# R9A09G057H register map
Vendor: Renesas Electronics; File version: 1.0
Registers are 32-bit, read-write, no defined reset value unless marked. A register's access mark holds for its fields unless they carry their own. Offsets are from the block's base; [hi:lo] are bit positions; lines under a group give offsets from that group; {n}, {i} and the like mark numbered series.

## R_GPIO — IO define file for gpio.
Base 0x10410020
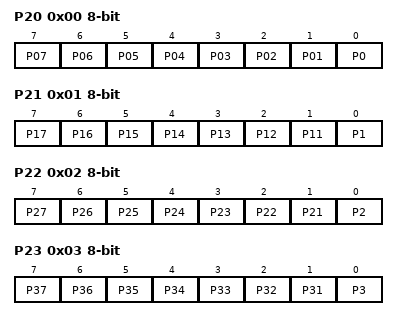
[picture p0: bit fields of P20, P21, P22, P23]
0x00 P20 8-bit
  [n] P{n:02} (n=1..7), [0] P0
0x01 P21 8-bit
  [n-10] P{n} (n=11..17), [0] P1
0x02 P22 8-bit
  [n-20] P{n} (n=21..27), [0] P2
0x03 P23 8-bit
  [n-30] P{n} (n=31..37), [0] P3
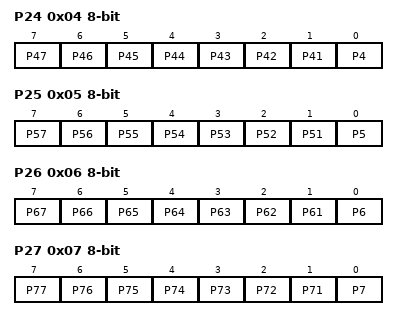
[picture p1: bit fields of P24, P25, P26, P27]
0x04 P24 8-bit
  [n-40] P{n} (n=41..47), [0] P4
0x05 P25 8-bit
  [n-50] P{n} (n=51..57), [0] P5
0x06 P26 8-bit
  [n-60] P{n} (n=61..67), [0] P6
0x07 P27 8-bit
  [n-70] P{n} (n=71..77), [0] P7
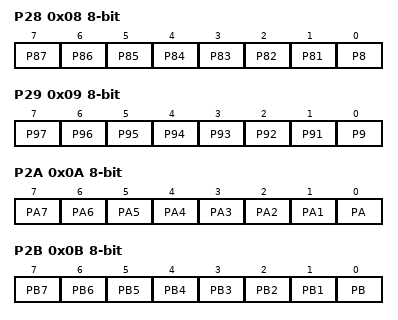
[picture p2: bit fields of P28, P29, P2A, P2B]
0x08 P28 8-bit
  [n-80] P{n} (n=81..87), [0] P8
0x09 P29 8-bit
  [n-90] P{n} (n=91..97), [0] P9
0x0A P2A 8-bit
  [n] PA{n} (n=1..7), [0] PA
0x0B P2B 8-bit
  [n] PB{n} (n=1..7), [0] PB
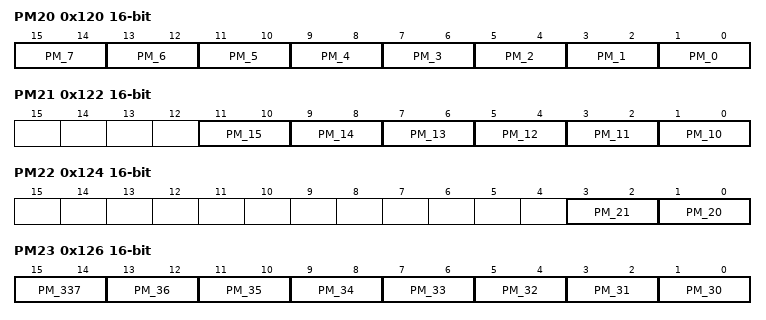
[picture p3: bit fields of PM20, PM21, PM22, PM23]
0x120 PM20 16-bit
  [2n+1:2n] PM_{n} (n=0..7)
0x122 PM21 16-bit
  [2n-19:2n-20] PM_{n} (n=10..15)
0x124 PM22 16-bit
  [3:2] PM_21, [1:0] PM_20
0x126 PM23 16-bit
  [15:14] PM_337, [2n-59:2n-60] PM_{n} (n=30..36)
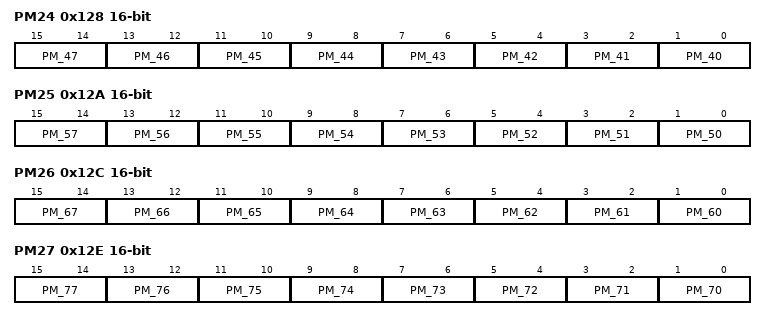
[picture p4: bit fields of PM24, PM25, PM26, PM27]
0x128 PM24 16-bit
  [2n-79:2n-80] PM_{n} (n=40..47)
0x12A PM25 16-bit
  [2n-99:2n-100] PM_{n} (n=50..57)
0x12C PM26 16-bit
  [2n-119:2n-120] PM_{n} (n=60..67)
0x12E PM27 16-bit
  [2n-139:2n-140] PM_{n} (n=70..77)
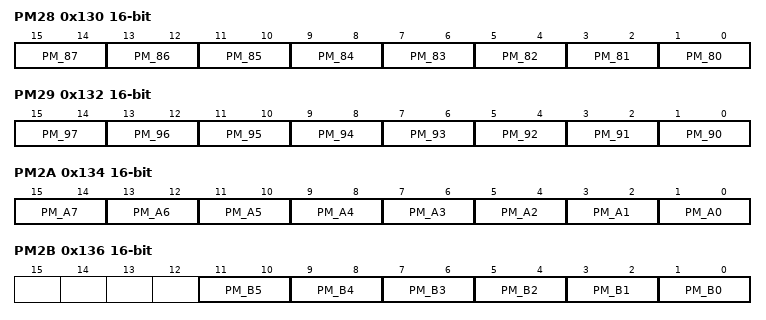
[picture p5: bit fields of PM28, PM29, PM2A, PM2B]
0x130 PM28 16-bit
  [2n-159:2n-160] PM_{n} (n=80..87)
0x132 PM29 16-bit
  [2n-179:2n-180] PM_{n} (n=90..97)
0x134 PM2A 16-bit
  [2n+1:2n] PM_A{n} (n=0..7)
0x136 PM2B 16-bit
  [2n+1:2n] PM_B{n} (n=0..5)
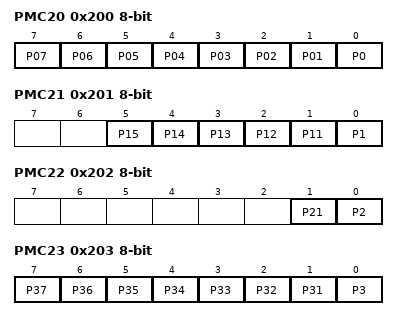
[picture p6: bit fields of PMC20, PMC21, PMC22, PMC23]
0x200 PMC20 8-bit
  [n] P{n:02} (n=1..7), [0] P0
0x201 PMC21 8-bit
  [n-10] P{n} (n=11..15), [0] P1
0x202 PMC22 8-bit
  [1] P21, [0] P2
0x203 PMC23 8-bit
  [n-30] P{n} (n=31..37), [0] P3
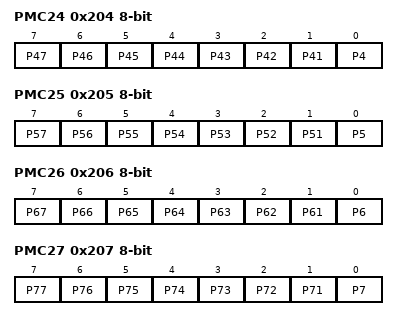
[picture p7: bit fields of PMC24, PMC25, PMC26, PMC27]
0x204 PMC24 8-bit
  [n-40] P{n} (n=41..47), [0] P4
0x205 PMC25 8-bit
  [n-50] P{n} (n=51..57), [0] P5
0x206 PMC26 8-bit
  [n-60] P{n} (n=61..67), [0] P6
0x207 PMC27 8-bit
  [n-70] P{n} (n=71..77), [0] P7
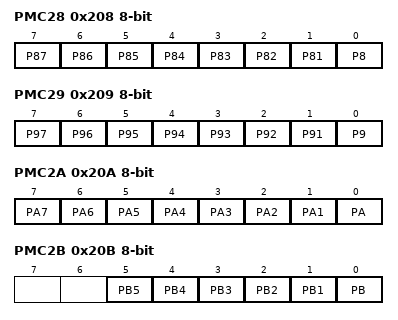
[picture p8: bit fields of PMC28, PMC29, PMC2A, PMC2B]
0x208 PMC28 8-bit
  [n-80] P{n} (n=81..87), [0] P8
0x209 PMC29 8-bit
  [n-90] P{n} (n=91..97), [0] P9
0x20A PMC2A 8-bit
  [n] PA{n} (n=1..7), [0] PA
0x20B PMC2B 8-bit
  [n] PB{n} (n=1..5), [0] PB
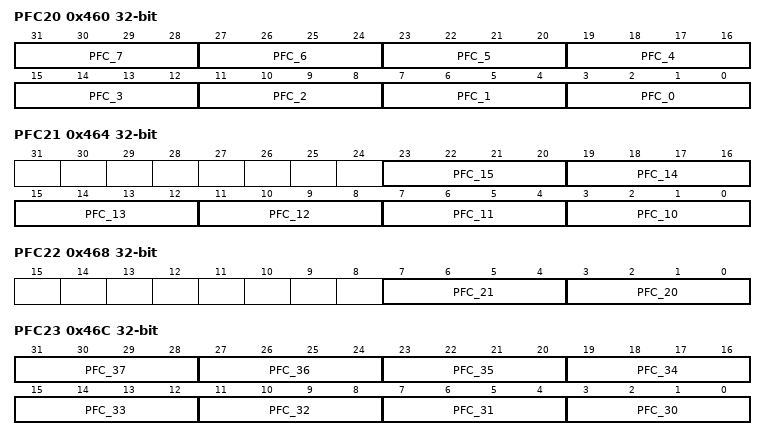
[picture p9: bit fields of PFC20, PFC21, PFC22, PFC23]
0x460 PFC20
  [4n+3:4n] PFC_{n} (n=0..7)
0x464 PFC21
  [4n-37:4n-40] PFC_{n} (n=10..15)
0x468 PFC22
  [7:4] PFC_21, [3:0] PFC_20
0x46C PFC23
  [4n-117:4n-120] PFC_{n} (n=30..37)
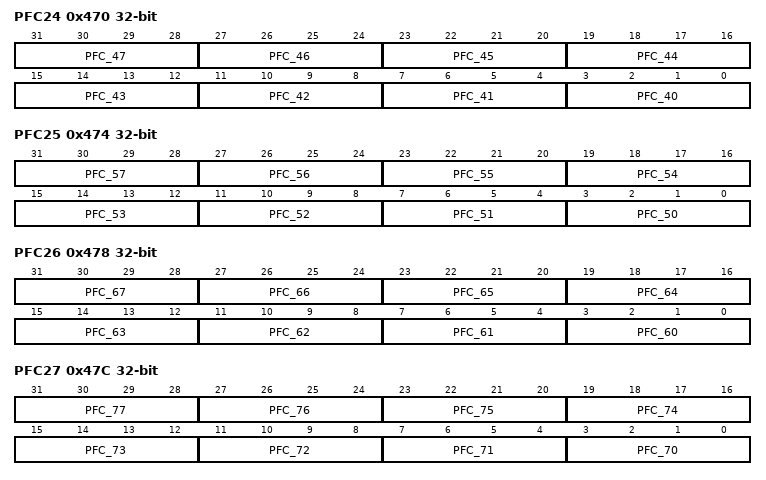
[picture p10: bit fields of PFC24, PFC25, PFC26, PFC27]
0x470 PFC24
  [4n-157:4n-160] PFC_{n} (n=40..47)
0x474 PFC25
  [4n-197:4n-200] PFC_{n} (n=50..57)
0x478 PFC26
  [4n-237:4n-240] PFC_{n} (n=60..67)
0x47C PFC27
  [4n-277:4n-280] PFC_{n} (n=70..77)
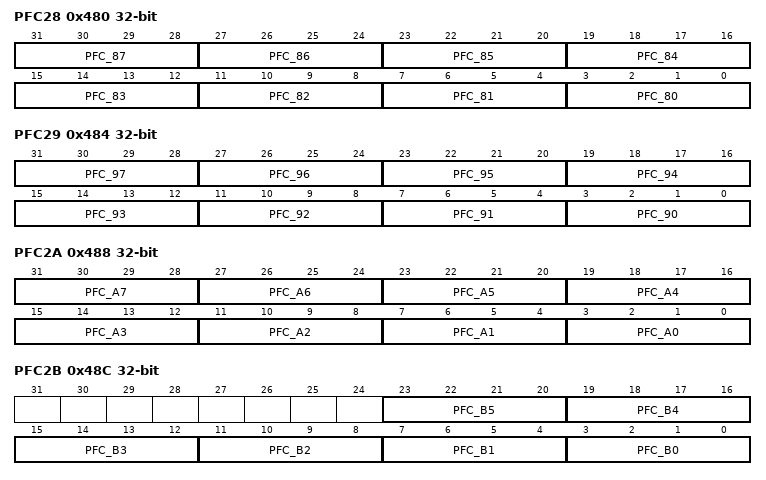
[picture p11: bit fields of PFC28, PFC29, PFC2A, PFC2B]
0x480 PFC28
  [4n-317:4n-320] PFC_{n} (n=80..87)
0x484 PFC29
  [4n-357:4n-360] PFC_{n} (n=90..97)
0x488 PFC2A
  [4n+3:4n] PFC_A{n} (n=0..7)
0x48C PFC2B
  [4n+3:4n] PFC_B{n} (n=0..5)
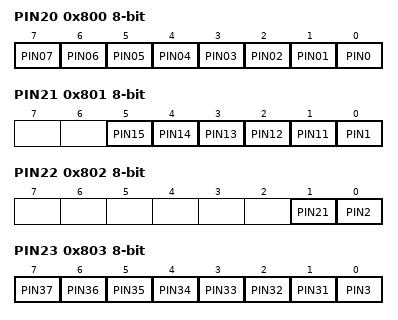
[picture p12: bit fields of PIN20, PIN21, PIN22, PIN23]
0x800 PIN20 8-bit ro
  [n] PIN{n:02} (n=1..7), [0] PIN0
0x801 PIN21 8-bit ro
  [n-10] PIN{n} (n=11..15), [0] PIN1
0x802 PIN22 8-bit ro
  [1] PIN21, [0] PIN2
0x803 PIN23 8-bit ro
  [n-30] PIN{n} (n=31..37), [0] PIN3
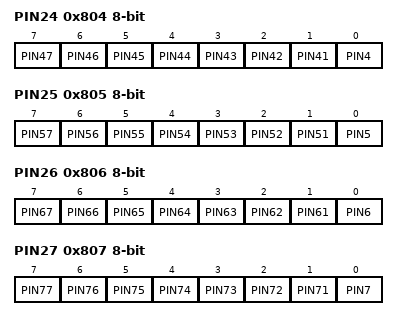
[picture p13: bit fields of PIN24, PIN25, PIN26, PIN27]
0x804 PIN24 8-bit ro
  [n-40] PIN{n} (n=41..47), [0] PIN4
0x805 PIN25 8-bit ro
  [n-50] PIN{n} (n=51..57), [0] PIN5
0x806 PIN26 8-bit ro
  [n-60] PIN{n} (n=61..67), [0] PIN6
0x807 PIN27 8-bit ro
  [n-70] PIN{n} (n=71..77), [0] PIN7
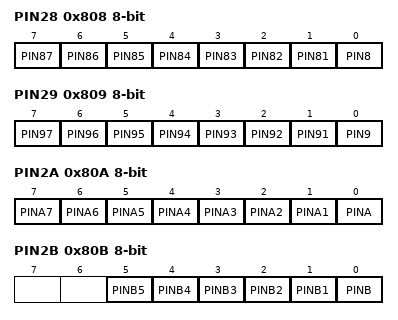
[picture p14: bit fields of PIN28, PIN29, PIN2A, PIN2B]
0x808 PIN28 8-bit ro
  [n-80] PIN{n} (n=81..87), [0] PIN8
0x809 PIN29 8-bit ro
  [n-90] PIN{n} (n=91..97), [0] PIN9
0x80A PIN2A 8-bit ro
  [n] PINA{n} (n=1..7), [0] PINA
0x80B PIN2B 8-bit ro
  [n] PINB{n} (n=1..5), [0] PINB
0xFF8 IOLH3_L
  [8n-239:8n-240] IOLH_{n} (n=30..33)
0xFFC IOLH3_H
  [8n-239:8n-240] IOLH_{n} (n=30..33)
0x1008 IOLH5_L
  [8n-399:8n-400] IOLH_{n} (n=50..53)
0x100C IOLH5_H
  [8n-399:8n-400] IOLH_{n} (n=50..53)
0x1010 IOLH6_L
  [8n-479:8n-480] IOLH_{n} (n=60..63)
0x1014 IOLH6_H
  [8n-479:8n-480] IOLH_{n} (n=60..63)
0x1018 IOLH7_L
  [8n-559:8n-560] IOLH_{n} (n=70..73)
0x101C IOLH7_H
  [8n-559:8n-560] IOLH_{n} (n=70..73)
0x1020 IOLH8_L
  [8n-639:8n-640] IOLH_{n} (n=80..83)
0x1024 IOLH8_H
  [8n-639:8n-640] IOLH_{n} (n=80..83)
0x1028 IOLH9_L
  [8n-719:8n-720] IOLH_{n} (n=90..93)
0x102C IOLH9_H
  [8n-719:8n-720] IOLH_{n} (n=90..93)
0x1030 IOLHA_L
  [8n+1:8n] IOLH_A{n} (n=0..3)
0x1034 IOLHA_H
  [8n+1:8n] IOLH_A{n} (n=0..3)
0x1038 IOLHB_L
  [8n+1:8n] IOLH_B{n} (n=0..3)
0x103C IOLHB_H
  [8n+1:8n] IOLH_B{n} (n=0..3)
0x1040 IOLHC_L
  [8n+1:8n] IOLH_C{n} (n=0..3)
0x1044 IOLHC_H
  [8n+1:8n] IOLH_C{n} (n=0..3)
0x1050 IOLHE_L
  [8n+1:8n] IOLH_E{n} (n=0..3)
0x1054 IOLHE_H
  [8n+1:8n] IOLH_E{n} (n=0..3)
0x1058 IOLHF_L
  [8n+1:8n] IOLH_F{n} (n=0..3)
0x105C IOLHF_H
  [8n+1:8n] IOLH_F{n} (n=0..3)
0x1060 IOLH10_L
  [8n-799:8n-800] IOLH_{n} (n=100..103)
0x1064 IOLH10_H
  [8n-799:8n-800] IOLH_{n} (n=100..103)
0x1068 IOLH11_L
  [8n-879:8n-880] IOLH_{n} (n=110..113)
0x106C IOLH11_H
  [8n-879:8n-880] IOLH_{n} (n=110..113)
0x1070 IOLH12_L
  [8n-959:8n-960] IOLH_{n} (n=120..123)
0x1074 IOLH12_H
  [8n-959:8n-960] IOLH_{n} (n=120..123)
0x1078 IOLH13_L
  [8n-1039:8n-1040] IOLH_{n} (n=130..133)
0x107C IOLH13_H
  [8n-1039:8n-1040] IOLH_{n} (n=130..133)
0x1080 IOLH14_L
  [8n-1119:8n-1120] IOLH_{n} (n=140..143)
0x1084 IOLH14_H
  [8n-1119:8n-1120] IOLH_{n} (n=140..143)
0x10E0 IOLH20_L
  [8n-1599:8n-1600] IOLH_{n} (n=200..203)
0x10E4 IOLH20_H
  [8n-1599:8n-1600] IOLH_{n} (n=200..203)
0x10E8 IOLH21_L
  [8n-1679:8n-1680] IOLH_{n} (n=210..213)
0x10EC IOLH21_H
  [8n-1679:8n-1680] IOLH_{n} (n=210..213)
0x10F0 IOLH22_L
  [8n-1759:8n-1760] IOLH_{n} (n=220..223)
0x10F4 IOLH22_H
  [8n-1759:8n-1760] IOLH_{n} (n=220..223)
0x10F8 IOLH23_L
  [8n-1839:8n-1840] IOLH_{n} (n=230..233)
0x10FC IOLH23_H
  [8n-1839:8n-1840] IOLH_{n} (n=230..233)
0x1100 IOLH24_L
  [8n-1919:8n-1920] IOLH_{n} (n=240..243)
0x1104 IOLH24_H
  [8n-1919:8n-1920] IOLH_{n} (n=240..243)
0x1108 IOLH25_L
  [8n-1999:8n-2000] IOLH_{n} (n=250..253)
0x110C IOLH25_H
  [8n-1999:8n-2000] IOLH_{n} (n=250..253)
0x1110 IOLH26_L
  [8n-2079:8n-2080] IOLH_{n} (n=260..263)
0x1114 IOLH26_H
  [8n-2079:8n-2080] IOLH_{n} (n=260..263)
0x1118 IOLH27_L
  [8n-2159:8n-2160] IOLH_{n} (n=270..273)
0x111C IOLH27_H
  [8n-2159:8n-2160] IOLH_{n} (n=270..273)
0x1120 IOLH28_L
  [8n-2239:8n-2240] IOLH_{n} (n=280..283)
0x1124 IOLH28_H
  [8n-2239:8n-2240] IOLH_{n} (n=280..283)
0x1128 IOLH29_L
  [8n-2319:8n-2320] IOLH_{n} (n=290..293)
0x112C IOLH29_H
  [8n-2319:8n-2320] IOLH_{n} (n=290..293)
0x1130 IOLH2A_L
  [8n+1:8n] IOLH_2A{n} (n=0..3)
0x1134 IOLH2A_H
  [8n+1:8n] IOLH_2A{n} (n=0..3)
0x1138 IOLH2B_L
  [8n+1:8n] IOLH_2B{n} (n=0..3)
0x113C IOLH2B_H
  [8n+1:8n] IOLH_2B{n} (n=0..3)
0x13F8 SR3_L
  [8n-240] SR_{n} (n=30..33)
0x13FC SR3_H
  [8n-240] SR_{n} (n=30..33)
0x1408 SR5_L
  [8n-400] SR_{n} (n=50..53)
0x140C SR5_H
  [8n-400] SR_{n} (n=50..53)
0x1410 SR6_L
  [8n-480] SR_{n} (n=60..63)
0x1414 SR6_H
  [8n-480] SR_{n} (n=60..63)
0x1418 SR7_L
  [8n-560] SR_{n} (n=70..73)
0x141C SR7_H
  [8n-560] SR_{n} (n=70..73)
0x1420 SR8_L
  [8n-640] SR_{n} (n=80..83)
0x1424 SR8_H
  [8n-640] SR_{n} (n=80..83)
0x1428 SR9_L
  [8n-720] SR_{n} (n=90..93)
0x142C SR9_H
  [8n-720] SR_{n} (n=90..93)
0x1430 SRA_L
  [8n] SR_A{n} (n=0..3)
0x1434 SRA_H
  [8n] SR_A{n} (n=0..3)
0x1438 SRB_L
  [8n] SR_B{n} (n=0..3)
0x143C SRB_H
  [8n] SR_B{n} (n=0..3)
0x1440 SRC_L
  [8n] SR_C{n} (n=0..3)
0x1444 SRC_H
  [8n] SR_C{n} (n=0..3)
0x1450 SRE_L
  [8n] SR_E{n} (n=0..3)
0x1454 SRE_H
  [8n] SR_E{n} (n=0..3)
0x1458 SRF_L
  [8n] SR_F{n} (n=0..3)
0x145C SRF_H
  [8n] SR_F{n} (n=0..3)
0x1460 SR10_L
  [8n-800] SR_{n} (n=100..103)
0x1464 SR10_H
  [8n-800] SR_{n} (n=100..103)
0x1468 SR11_L
  [8n-880] SR_{n} (n=110..113)
0x146C SR11_H
  [8n-880] SR_{n} (n=110..113)
0x1470 SR12_L
  [8n-960] SR_{n} (n=120..123)
0x1474 SR12_H
  [8n-960] SR_{n} (n=120..123)
0x1478 SR13_L
  [8n-1040] SR_{n} (n=130..133)
0x147C SR13_H
  [8n-1040] SR_{n} (n=130..133)
0x1480 SR14_L
  [8n-1120] SR_{n} (n=140..143)
0x1484 SR14_H
  [8n-1120] SR_{n} (n=140..143)
0x14E0 SR20_L
  [8n-1600] SR_{n} (n=200..203)
0x14E4 SR20_H
  [8n-1600] SR_{n} (n=200..203)
0x14E8 SR21_L
  [8n-1680] SR_{n} (n=210..213)
0x14EC SR21_H
  [8n-1680] SR_{n} (n=210..213)
0x14F8 SR23_L
  [8n-1840] SR_{n} (n=230..233)
0x14FC SR23_H
  [8n-1840] SR_{n} (n=230..233)
0x1500 SR24_L
  [8n-1920] SR_{n} (n=240..243)
0x1504 SR24_H
  [8n-1920] SR_{n} (n=240..243)
0x1508 SR25_L
  [8n-2000] SR_{n} (n=250..253)
0x150C SR25_H
  [8n-2000] SR_{n} (n=250..253)
0x1510 SR26_L
  [8n-2080] SR_{n} (n=260..263)
0x1514 SR26_H
  [8n-2080] SR_{n} (n=260..263)
0x1518 SR27_L
  [8n-2160] SR_{n} (n=270..273)
0x151C SR27_H
  [8n-2160] SR_{n} (n=270..273)
0x1520 SR28_L
  [8n-2240] SR_{n} (n=280..283)
0x1524 SR28_H
  [8n-2240] SR_{n} (n=280..283)
0x1528 SR29_L
  [8n-2320] SR_{n} (n=290..293)
0x152C SR29_H
  [8n-2320] SR_{n} (n=290..293)
0x1530 SR2A_L
  [8n] SR_2A{n} (n=0..3)
0x1534 SR2A_H
  [8n] SR_2A{n} (n=0..3)
0x1538 SR2B_L
  [8n] SR_2B{n} (n=0..3)
0x153C SR2B_H
  [8n] SR_2B{n} (n=0..3)
0x17F8 IEN3_L
  [8n-240] IEN_{n} (n=30..33)
0x17FC IEN3_H
  [8n-240] IEN_{n} (n=30..33)
0x1828 IEN9_L
  [8n-720] IEN_{n} (n=90..93)
0x182C IEN9_H
  [8n-720] IEN_{n} (n=90..93)
0x1830 IENA_L
  [8n] IEN_A{n} (n=0..3)
0x1834 IENA_H
  [8n] IEN_A{n} (n=0..3)
0x1838 IENB_L
  [8n] IEN_B{n} (n=0..3)
0x183C IENB_H
  [8n] IEN_B{n} (n=0..3)
0x1840 IENC_L
  [8n] IEN_C{n} (n=0..3)
0x1844 IENC_H
  [8n] IEN_C{n} (n=0..3)
0x1858 IENF_L
  [8n] IEN_F{n} (n=0..3)
0x185C IENF_H
  [8n] IEN_F{n} (n=0..3)
0x1870 IEN12_L
  [8n-960] IEN_{n} (n=120..123)
0x1874 IEN12_H
  [8n-960] IEN_{n} (n=120..123)
0x1878 IEN2B_L
  [8n] IEN_2B{n} (n=0..3)
0x1878 IEN2B_H
  [8n] IEN_2B{n} (n=0..3)
0x1C08 PUPD5_L
  [8n-399:8n-400] PUPD_{n} (n=50..53)
0x1C0C PUPD5_H
  [8n-399:8n-400] PUPD_{n} (n=50..53)
0x1C10 PUPD6_L
  [8n-479:8n-480] PUPD_{n} (n=60..63)
0x1C14 PUPD6_H
  [8n-479:8n-480] PUPD_{n} (n=60..63)
0x1C18 PUPD7_L
  [8n-559:8n-560] PUPD_{n} (n=70..73)
0x1C1C PUPD7_H
  [8n-559:8n-560] PUPD_{n} (n=70..73)
0x1C20 PUPD8_L
  [8n-639:8n-640] PUPD_{n} (n=80..83)
0x1C24 PUPD8_H
  [8n-639:8n-640] PUPD_{n} (n=80..83)
0x1C28 PUPD9_L
  [8n-719:8n-720] PUPD_{n} (n=90..93)
0x1C2C PUPD9_H
  [8n-719:8n-720] PUPD_{n} (n=90..93)
0x1C30 PUPDA_L
  [8n+1:8n] PUPD_A{n} (n=0..3)
0x1C34 PUPDA_H
  [8n+1:8n] PUPD_A{n} (n=0..3)
0x1C38 PUPDB_L
  [8n+1:8n] PUPD_B{n} (n=0..3)
0x1C3C PUPDB_H
  [8n+1:8n] PUPD_B{n} (n=0..3)
0x1C40 PUPDC_L
  [8n+1:8n] PUPD_C{n} (n=0..3)
0x1C44 PUPDC_H
  [8n+1:8n] PUPD_C{n} (n=0..3)
0x1C58 PUPDF_L
  [8n+1:8n] PUPD_F{n} (n=0..3)
0x1C5C PUPDF_H
  [8n+1:8n] PUPD_F{n} (n=0..3)
0x1C60 PUPD10_L
  [8n-799:8n-800] PUPD_{n} (n=100..103)
0x1C64 PUPD10_H
  [8n-799:8n-800] PUPD_{n} (n=100..103)
0x1C68 PUPD11_L
  [8n-879:8n-880] PUPD_{n} (n=110..113)
0x1C6C PUPD11_H
  [8n-879:8n-880] PUPD_{n} (n=110..113)
0x1C70 PUPD12_L
  [8n-959:8n-960] PUPD_{n} (n=120..123)
0x1C74 PUPD12_H
  [8n-959:8n-960] PUPD_{n} (n=120..123)
0x1C78 PUPD13_L
  [8n-1039:8n-1040] PUPD_{n} (n=130..133)
0x1C7C PUPD13_H
  [8n-1039:8n-1040] PUPD_{n} (n=130..133)
0x1C80 PUPD14_L
  [8n-1119:8n-1120] PUPD_{n} (n=140..143)
0x1C84 PUPD14_H
  [8n-1119:8n-1120] PUPD_{n} (n=140..143)
0x1CE0 PUPD20_L
  [8n-1599:8n-1600] PUPD_{n} (n=200..203)
0x1CE4 PUPD20_H
  [8n-1599:8n-1600] PUPD_{n} (n=200..203)
0x1CE8 PUPD21_L
  [8n-1679:8n-1680] PUPD_{n} (n=210..213)
0x1CEC PUPD21_H
  [8n-1679:8n-1680] PUPD_{n} (n=210..213)
0x1CF0 PUPD22_L
  [8n-1759:8n-1760] PUPD_{n} (n=220..223)
0x1CF4 PUPD22_H
  [8n-1759:8n-1760] PUPD_{n} (n=220..223)
0x1CF8 PUPD23_L
  [8n-1839:8n-1840] PUPD_{n} (n=230..233)
0x1CFC PUPD23_H
  [8n-1839:8n-1840] PUPD_{n} (n=230..233)
0x1D00 PUPD24_L
  [8n-1919:8n-1920] PUPD_{n} (n=240..243)
0x1D04 PUPD24_H
  [8n-1919:8n-1920] PUPD_{n} (n=240..243)
0x1D08 PUPD25_L
  [8n-1999:8n-2000] PUPD_{n} (n=250..253)
0x1D0C PUPD25_H
  [8n-1999:8n-2000] PUPD_{n} (n=250..253)
0x1D10 PUPD26_L
  [8n-2079:8n-2080] PUPD_{n} (n=260..263)
0x1D14 PUPD26_H
  [8n-2079:8n-2080] PUPD_{n} (n=260..263)
0x1D18 PUPD27_L
  [8n-2159:8n-2160] PUPD_{n} (n=270..273)
0x1D1C PUPD27_H
  [8n-2159:8n-2160] PUPD_{n} (n=270..273)
0x1D20 PUPD28_L
  [8n-2239:8n-2240] PUPD_{n} (n=280..283)
0x1D24 PUPD28_H
  [8n-2239:8n-2240] PUPD_{n} (n=280..283)
0x1D28 PUPD29_L
  [8n-2319:8n-2320] PUPD_{n} (n=290..293)
0x1D2C PUPD29_H
  [8n-2319:8n-2320] PUPD_{n} (n=290..293)
0x1D30 PUPD2A_L
  [8n+1:8n] PUPD_2A{n} (n=0..3)
0x1D34 PUPD2A_H
  [8n+1:8n] PUPD_2A{n} (n=0..3)
0x1D38 PUPD2B_L
  [8n+1:8n] PUPD_2B{n} (n=0..3)
0x1D3C PUPD2B_H
  [8n+1:8n] PUPD_2B{n} (n=0..3)
0x1FE8 FILONOFF1_L
  [8n-80] FILONOFF_{n} (n=10..13)
0x1FEC FILONOFF1_H
  [8n-80] FILONOFF_{n} (n=10..13)
0x20E0 FILONOFF20_L
  [8n-1600] FILONOFF_{n} (n=200..203)
0x20E4 FILONOFF20_H
  [8n-1600] FILONOFF_{n} (n=200..203)
0x20E8 FILONOFF21_L
  [8n-1680] FILONOFF_{n} (n=210..213)
0x20EC FILONOFF21_H
  [8n-1680] FILONOFF_{n} (n=210..213)
0x20F0 FILONOFF22_L
  [8n-1760] FILONOFF_{n} (n=220..223)
0x20F4 FILONOFF22_H
  [8n-1760] FILONOFF_{n} (n=220..223)
0x20F8 FILONOFF23_L
  [8n-1840] FILONOFF_{n} (n=230..233)
0x20FC FILONOFF23_H
  [8n-1840] FILONOFF_{n} (n=230..233)
0x2100 FILONOFF24_L
  [8n-1920] FILONOFF_{n} (n=240..243)
0x2104 FILONOFF24_H
  [8n-1920] FILONOFF_{n} (n=240..243)
0x2108 FILONOFF25_L
  [8n-2000] FILONOFF_{n} (n=250..253)
0x210C FILONOFF25_H
  [8n-2000] FILONOFF_{n} (n=250..253)
0x2110 FILONOFF26_L
  [8n-2080] FILONOFF_{n} (n=260..263)
0x2114 FILONOFF26_H
  [8n-2080] FILONOFF_{n} (n=260..263)
0x2118 FILONOFF27_L
  [8n-2160] FILONOFF_{n} (n=270..273)
0x211C FILONOFF27_H
  [8n-2160] FILONOFF_{n} (n=270..273)
0x2120 FILONOFF28_L
  [8n-2240] FILONOFF_{n} (n=280..283)
0x2124 FILONOFF28_H
  [8n-2240] FILONOFF_{n} (n=280..283)
0x2128 FILONOFF29_L
  [8n-2320] FILONOFF_{n} (n=290..293)
0x212C FILONOFF29_H
  [8n-2320] FILONOFF_{n} (n=290..293)
0x2130 FILONOFF2A_L
  [8n] FILONOFF_2A{n} (n=0..3)
0x2134 FILONOFF2A_H
  [8n] FILONOFF_2A{n} (n=0..3)
0x2138 FILONOFF2B_L
  [8n] FILONOFF_2B{n} (n=0..3)
0x213C FILONOFF2B_H
  [8n] FILONOFF_2B{n} (n=0..3)
0x23E8 FILNUM1_L
  [8n-79:8n-80] FILNUM_{n} (n=10..13)
0x23EC FILNUM1_H
  [8n-79:8n-80] FILNUM_{n} (n=10..13)
0x24E0 FILNUM20_L
  [8n-1599:8n-1600] FILNUM_{n} (n=200..203)
0x24E4 FILNUM20_H
  [8n-1599:8n-1600] FILNUM_{n} (n=200..203)
0x24E8 FILNUM21_L
  [8n-1679:8n-1680] FILNUM_{n} (n=210..213)
0x24EC FILNUM21_H
  [8n-1679:8n-1680] FILNUM_{n} (n=210..213)
0x24F0 FILNUM22_L
  [8n-1759:8n-1760] FILNUM_{n} (n=220..223)
0x24F4 FILNUM22_H
  [8n-1759:8n-1760] FILNUM_{n} (n=220..223)
0x24F8 FILNUM23_L
  [8n-1839:8n-1840] FILNUM_{n} (n=230..233)
0x24FC FILNUM23_H
  [8n-1839:8n-1840] FILNUM_{n} (n=230..233)
0x2500 FILNUM24_L
  [8n-1919:8n-1920] FILNUM_{n} (n=240..243)
0x2504 FILNUM24_H
  [8n-1919:8n-1920] FILNUM_{n} (n=240..243)
0x2508 FILNUM25_L
  [8n-1999:8n-2000] FILNUM_{n} (n=250..253)
0x250C FILNUM25_H
  [8n-1999:8n-2000] FILNUM_{n} (n=250..253)
0x2510 FILNUM26_L
  [8n-2079:8n-2080] FILNUM_{n} (n=260..263)
0x2514 FILNUM26_H
  [8n-2079:8n-2080] FILNUM_{n} (n=260..263)
0x2518 FILNUM27_L
  [8n-2159:8n-2160] FILNUM_{n} (n=270..273)
0x251C FILNUM27_H
  [8n-2159:8n-2160] FILNUM_{n} (n=270..273)
0x2520 FILNUM28_L
  [8n-2239:8n-2240] FILNUM_{n} (n=280..283)
0x2524 FILNUM28_H
  [8n-2239:8n-2240] FILNUM_{n} (n=280..283)
0x2528 FILNUM29_L
  [8n-2319:8n-2320] FILNUM_{n} (n=290..293)
0x252C FILNUM29_H
  [8n-2319:8n-2320] FILNUM_{n} (n=290..293)
0x2530 FILNUM2A_L
  [8n+1:8n] FILNUM_2A{n} (n=0..3)
0x2534 FILNUM2A_H
  [8n+1:8n] FILNUM_2A{n} (n=0..3)
0x2538 FILNUM2B_L
  [8n+1:8n] FILNUM_2B{n} (n=0..3)
0x253C FILNUM2B_H
  [8n+1:8n] FILNUM_2B{n} (n=0..3)
0x27E8 FILCLKSEL1_L
  [8n-79:8n-80] FILCLKSEL_{n} (n=10..13)
0x27EC FILCLKSEL1_H
  [8n-79:8n-80] FILCLKSEL_{n} (n=10..13)
0x28E0 FILCLKSEL20_L
  [8n-1599:8n-1600] FILCLKSEL_{n} (n=200..203)
0x28E4 FILCLKSEL20_H
  [8n-1599:8n-1600] FILCLKSEL_{n} (n=200..203)
0x28E8 FILCLKSEL21_L
  [8n-1679:8n-1680] FILCLKSEL_{n} (n=210..213)
0x28EC FILCLKSEL21_H
  [8n-1679:8n-1680] FILCLKSEL_{n} (n=210..213)
0x28F0 FILCLKSEL22_L
  [8n-1759:8n-1760] FILCLKSEL_{n} (n=220..223)
0x28F4 FILCLKSEL22_H
  [8n-1759:8n-1760] FILCLKSEL_{n} (n=220..223)
0x28F8 FILCLKSEL23_L
  [8n-1839:8n-1840] FILCLKSEL_{n} (n=230..233)
0x28FC FILCLKSEL23_H
  [8n-1839:8n-1840] FILCLKSEL_{n} (n=230..233)
0x2900 FILCLKSEL24_L
  [8n-1919:8n-1920] FILCLKSEL_{n} (n=240..243)
0x2904 FILCLKSEL24_H
  [8n-1919:8n-1920] FILCLKSEL_{n} (n=240..243)
0x2908 FILCLKSEL25_L
  [8n-1999:8n-2000] FILCLKSEL_{n} (n=250..253)
0x290C FILCLKSEL25_H
  [8n-1999:8n-2000] FILCLKSEL_{n} (n=250..253)
0x2910 FILCLKSEL26_L
  [8n-2079:8n-2080] FILCLKSEL_{n} (n=260..263)
0x2914 FILCLKSEL26_H
  [8n-2079:8n-2080] FILCLKSEL_{n} (n=260..263)
0x2918 FILCLKSEL27_L
  [8n-2159:8n-2160] FILCLKSEL_{n} (n=270..273)
0x291C FILCLKSEL27_H
  [8n-2159:8n-2160] FILCLKSEL_{n} (n=270..273)
0x2920 FILCLKSEL28_L
  [8n-2239:8n-2240] FILCLKSEL_{n} (n=280..283)
0x2924 FILCLKSEL28_H
  [8n-2239:8n-2240] FILCLKSEL_{n} (n=280..283)
0x2928 FILCLKSEL29_L
  [8n-2319:8n-2320] FILCLKSEL_{n} (n=290..293)
0x292C FILCLKSEL29_H
  [8n-2319:8n-2320] FILCLKSEL_{n} (n=290..293)
0x2930 FILCLKSEL2A_L
  [8n+1:8n] FILCLKSEL_2A{n} (n=0..3)
0x2934 FILCLKSEL2A_H
  [8n+1:8n] FILCLKSEL_2A{n} (n=0..3)
0x2938 FILCLKSEL2B_L
  [8n+1:8n] FILCLKSEL_2B{n} (n=0..3)
0x293C FILCLKSEL2B_H
  [8n+1:8n] FILCLKSEL_2B{n} (n=0..3)
0x2CE0 ISEL20_L
  [8n-1600] ISEL_{n} (n=200..203)
0x2CE4 ISEL20_H
  [8n-1600] ISEL_{n} (n=200..203)
0x2CE8 ISEL21_L
  [8n-1680] ISEL_{n} (n=210..213)
0x2CEC ISEL21_H
  [8n-1680] ISEL_{n} (n=210..213)
0x2CF0 ISEL22_L
  [8n-1760] ISEL_{n} (n=220..223)
0x2CF4 ISEL22_H
  [8n-1760] ISEL_{n} (n=220..223)
0x2CF8 ISEL23_L
  [8n-1840] ISEL_{n} (n=230..233)
0x2CFC ISEL23_H
  [8n-1840] ISEL_{n} (n=230..233)
0x2D00 ISEL24_L
  [8n-1920] ISEL_{n} (n=240..243)
0x2D04 ISEL24_H
  [8n-1920] ISEL_{n} (n=240..243)
0x2D08 ISEL25_L
  [8n-2000] ISEL_{n} (n=250..253)
0x2D0C ISEL25_H
  [8n-2000] ISEL_{n} (n=250..253)
0x2D10 ISEL26_L
  [8n-2080] ISEL_{n} (n=260..263)
0x2D14 ISEL26_H
  [8n-2080] ISEL_{n} (n=260..263)
0x2D18 ISEL27_L
  [8n-2160] ISEL_{n} (n=270..273)
0x2D1C ISEL27_H
  [8n-2160] ISEL_{n} (n=270..273)
0x2D20 ISEL28_L
  [8n-2240] ISEL_{n} (n=280..283)
0x2D24 ISEL28_H
  [8n-2240] ISEL_{n} (n=280..283)
0x2D28 ISEL29_L
  [8n-2320] ISEL_{n} (n=290..293)
0x2D2C ISEL29_H
  [8n-2320] ISEL_{n} (n=290..293)
0x2D30 ISEL2A_L
  [8n] ISEL_2A{n} (n=0..3)
0x2D34 ISEL2A_H
  [8n] ISEL_2A{n} (n=0..3)
0x2D38 ISEL2B_L
  [8n] ISEL_2B{n} (n=0..3)
0x2D3C ISEL2B_H
  [8n] ISEL_2B{n} (n=0..3)
0x3008 NOD5_L
  [8n-400] NOD_{n} (n=50..53)
0x300C NOD5_H
  [8n-400] NOD_{n} (n=50..53)
0x30E0 NOD20_L
  [8n-1600] NOD_{n} (n=200..203)
0x30E4 NOD20_H
  [8n-1600] NOD_{n} (n=200..203)
0x30E8 NOD21_L
  [8n-1680] NOD_{n} (n=210..213)
0x30EC NOD21_H
  [8n-1680] NOD_{n} (n=210..213)
0x30F0 NOD22_L
  [8n-1760] NOD_{n} (n=220..223)
0x30F4 NOD22_H
  [8n-1760] NOD_{n} (n=220..223)
0x30F8 NOD23_L
  [8n-1840] NOD_{n} (n=230..233)
0x30FC NOD23_H
  [8n-1840] NOD_{n} (n=230..233)
0x3100 NOD24_L
  [8n-1920] NOD_{n} (n=240..243)
0x3104 NOD24_H
  [8n-1920] NOD_{n} (n=240..243)
0x3108 NOD25_L
  [8n-2000] NOD_{n} (n=250..253)
0x310C NOD25_H
  [8n-2000] NOD_{n} (n=250..253)
0x3110 NOD26_L
  [8n-2080] NOD_{n} (n=260..263)
0x3114 NOD26_H
  [8n-2080] NOD_{n} (n=260..263)
0x3118 NOD27_L
  [8n-2160] NOD_{n} (n=270..273)
0x311C NOD27_H
  [8n-2160] NOD_{n} (n=270..273)
0x3120 NOD28_L
  [8n-2240] NOD_{n} (n=280..283)
0x3124 NOD28_H
  [8n-2240] NOD_{n} (n=280..283)
0x3128 NOD29_L
  [8n-2320] NOD_{n} (n=290..293)
0x312C NOD29_H
  [8n-2320] NOD_{n} (n=290..293)
0x3130 NOD2A_L
  [8n] NOD_2A{n} (n=0..3)
0x3134 NOD2A_H
  [8n] NOD_2A{n} (n=0..3)
0x3138 NOD2B_L
  [8n] NOD_2B{n} (n=0..3)
0x313C NOD2B_H
  [8n] NOD_2B{n} (n=0..3)
0x34E0 SMT20_L
  [8n-1600] SMT_{n} (n=200..203)
0x34E4 SMT20_H
  [8n-1600] SMT_{n} (n=200..203)
0x34E8 SMT21_L
  [8n-1680] SMT_{n} (n=210..213)
0x34EC SMT21_H
  [8n-1680] SMT_{n} (n=210..213)
0x34F8 SMT23_L
  [8n-1840] SMT_{n} (n=230..233)
0x34FC SMT23_H
  [8n-1840] SMT_{n} (n=230..233)
0x3500 SMT24_L
  [8n-1920] SMT_{n} (n=240..243)
0x3504 SMT24_H
  [8n-1920] SMT_{n} (n=240..243)
0x3508 SMT25_L
  [8n-2000] SMT_{n} (n=250..253)
0x350C SMT25_H
  [8n-2000] SMT_{n} (n=250..253)
0x3510 SMT26_L
  [8n-2080] SMT_{n} (n=260..263)
0x3514 SMT26_H
  [8n-2080] SMT_{n} (n=260..263)
0x3518 SMT27_L
  [8n-2160] SMT_{n} (n=270..273)
0x351C SMT27_H
  [8n-2160] SMT_{n} (n=270..273)
0x3520 SMT28_L
  [8n-2240] SMT_{n} (n=280..283)
0x3524 SMT28_H
  [8n-2240] SMT_{n} (n=280..283)
0x3528 SMT29_L
  [8n-2320] SMT_{n} (n=290..293)
0x352C SMT29_H
  [8n-2320] SMT_{n} (n=290..293)
0x3530 SMT2A_L
  [8n] SMT_2A{n} (n=0..3)
0x3534 SMT2A_H
  [8n] SMT_2A{n} (n=0..3)
0x3538 SMT2B_L
  [8n] SMT_2B{n} (n=0..3)
0x353C SMT2B_H
  [8n] SMT_2B{n} (n=0..3)
{0x37E0+i} ELC_PGR[{i}] (i=0..1) 8-bit
  [7:0] PGR
{0x37E2+i} ELC_PGC[{i}] (i=0..1) 8-bit
  [6:4] PGCO, [2] PGCOVE, [1:0] PGCI
{0x37E4+4i} PDBF[{i}] (i=0..1) group — PDBF register group
  0x00 ELC_PDBF 8-bit
{0x37EC+i} ELC_PEL[{i}] (i=0..3) 8-bit
  [6:5] PSM, [4:3] PSP, [2:0] PSB
0x37F0 ELC_DPTC 8-bit
  [n] PTC{n} (n=0..3)
0x37F1 PFC_ELC_ELSR2 8-bit
  [7:4] PES, [3:2] PEG
0x3BE0 PFC_OSCBYPS
  [21:20] OSCSF2, [19:18] OSCSF1, [10] OSCPW2, [9] OSCPW1, [8] OSCPW0, [2] OSCBYPS2, [1] OSCBYPS1, [0] OSCBYPS0
0x3BE4 PWPR
  [6] REGWE_A, [5] REGWE_B
0x3BE8 PFC_FILONOFF_IRQ
  [2n] IRQ{n} (n=0..15)
0x3BEC PFC_FILNUM_IRQ
  [2n+1:2n] IRQ{n} (n=0..15)
0x3BF0 PFC_FILCLKSEL_IRQ
  [2n+1:2n] IRQ{n} (n=0..15)
0x3BF4 PFC_FILONOFF_DMAC_REQ
  [2n] DMAC_REQ{n} (n=0..4)
0x3BF8 PFC_FILNUM_DMAC_REQ
  [2n+1:2n] DMAC_REQ{n} (n=0..4)
0x3BFC PFC_FILCLKSEL_DMAC_REQ
  [2n+1:2n] DMAC_REQ{n} (n=0..4)
0x3C20 PFC_OEN
  [n] OEN{n} (n=0..5)
